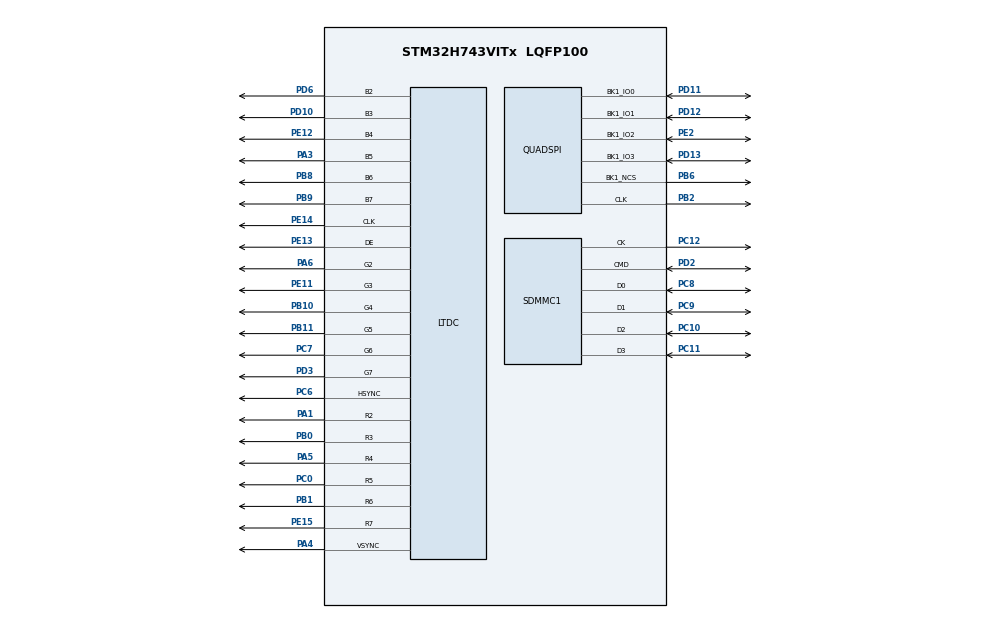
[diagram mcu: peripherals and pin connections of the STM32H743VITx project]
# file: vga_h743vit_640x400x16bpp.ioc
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CORTEX_M7.CPU_DCache=Disabled
CORTEX_M7.CPU_ICache=Enabled
DMA2D.ColorMode=DMA2D_OUTPUT_RGB565
FATFS._FS_LOCK=5
FATFS._FS_NORTC=0
FATFS._MAX_SS=4096
FATFS._USE_LFN=1
LTDC.ActiveH=400
LTDC.ActiveW=640
LTDC.Alpha_L0=255
LTDC.BlendingFactor1_L0=LTDC_BLENDING_FACTOR1_PAxCA
LTDC.BlendingFactor2_L0=LTDC_BLENDING_FACTOR2_PAxCA
LTDC.HBP=48
LTDC.HFP=16
LTDC.HSync=96
LTDC.ImageHeight_L0=400
LTDC.ImageWidth_L0=640
LTDC.Layers=0
LTDC.PixelFormat_L0=LTDC_PIXEL_FORMAT_RGB565
LTDC.VBP=73
LTDC.VFP=50
LTDC.VSync=2
LTDC.WindowX1_L0=640
LTDC.WindowY1_L0=400
Mcu.Family=STM32H7
Mcu.Name=STM32H743VITx
Mcu.Package=LQFP100
NVIC.PriorityGroup=NVIC_PRIORITYGROUP_4
NVIC.SDMMC1_IRQn=true\:0\:0\:false\:false\:true\:true
NVIC.TIM7_IRQn=true\:0\:0\:false\:false\:true\:false
NVIC.TimeBase=TIM7_IRQn
NVIC.TimeBaseIP=TIM7
PA1.Mode=RGB666
PA1.Signal=LTDC_R2
PA13.Mode=Trace_Asynchronous_SW
PA13.Signal=SYS_JTMS-SWDIO
PA14.Mode=Trace_Asynchronous_SW
PA14.Signal=SYS_JTCK-SWCLK
PA3.Mode=RGB666
PA3.Signal=LTDC_B5
PA4.Mode=RGB666
PA4.Signal=LTDC_VSYNC
PA5.Mode=RGB666
PA5.Signal=LTDC_R4
PA6.Mode=RGB666
PA6.Signal=LTDC_G2
PB0.Mode=RGB666
PB0.Signal=LTDC_R3
PB1.Mode=RGB666
PB1.Signal=LTDC_R6
PB10.Mode=RGB666
PB10.Signal=LTDC_G4
PB11.Mode=RGB666
PB11.Signal=LTDC_G5
PB2.Mode=Single Bank 1
PB2.Signal=QUADSPI_CLK
PB3.Mode=Trace_Asynchronous_SW
PB3.Signal=SYS_JTDO-SWO
PB6.Mode=Single Bank 1
PB6.Signal=QUADSPI_BK1_NCS
PB8.Mode=RGB666
PB8.Signal=LTDC_B6
PB9.Mode=RGB666
PB9.Signal=LTDC_B7
PC0.Mode=RGB666
PC0.Signal=LTDC_R5
PC10.Mode=SD_4_bits_Wide_bus
PC10.Signal=SDMMC1_D2
PC11.Mode=SD_4_bits_Wide_bus
PC11.Signal=SDMMC1_D3
PC12.Mode=SD_4_bits_Wide_bus
PC12.Signal=SDMMC1_CK
PC14-OSC32_IN.Mode=LSE-External-Oscillator
PC14-OSC32_IN.Signal=RCC_OSC32_IN
PC15-OSC32_OUT.Mode=LSE-External-Oscillator
PC15-OSC32_OUT.Signal=RCC_OSC32_OUT
PC6.Mode=RGB666
PC6.Signal=LTDC_HSYNC
PC7.Mode=RGB666
PC7.Signal=LTDC_G6
PC8.Mode=SD_4_bits_Wide_bus
PC8.Signal=SDMMC1_D0
PC9.Mode=SD_4_bits_Wide_bus
PC9.Signal=SDMMC1_D1
PD10.Mode=RGB666
PD10.Signal=LTDC_B3
PD11.Mode=Single Bank 1
PD11.Signal=QUADSPI_BK1_IO0
PD12.Mode=Single Bank 1
PD12.Signal=QUADSPI_BK1_IO1
PD13.Mode=Single Bank 1
PD13.Signal=QUADSPI_BK1_IO3
PD2.Mode=SD_4_bits_Wide_bus
PD2.Signal=SDMMC1_CMD
PD3.Mode=RGB666
PD3.Signal=LTDC_G7
PD6.Mode=RGB666
PD6.Signal=LTDC_B2
PE11.Mode=RGB666
PE11.Signal=LTDC_G3
PE12.Mode=RGB666
PE12.Signal=LTDC_B4
PE13.Mode=RGB666
PE13.Signal=LTDC_DE
PE14.Mode=RGB666
PE14.Signal=LTDC_CLK
PE15.Mode=RGB666
PE15.Signal=LTDC_R7
PE2.Mode=Single Bank 1
PE2.Signal=QUADSPI_BK1_IO2
PH0-OSC_IN.Mode=HSE-External-Oscillator
PH0-OSC_IN.Signal=RCC_OSC_IN
PH1-OSC_OUT.Mode=HSE-External-Oscillator
PH1-OSC_OUT.Signal=RCC_OSC_OUT
ProjectManager.HeapSize=0x200
ProjectManager.StackSize=0x800
ProjectManager.TargetToolchain=TrueSTUDIO
RCC.ADCFreq_Value=50390625
RCC.APB1Freq_Value=100000000
RCC.APB2Freq_Value=100000000
RCC.APB3Freq_Value=100000000
RCC.APB4Freq_Value=100000000
RCC.CortexFreq_Value=400000000
RCC.D1PPRE=RCC_APB3_DIV2
RCC.D2PPRE1=RCC_APB1_DIV2
RCC.D2PPRE2=RCC_APB2_DIV2
RCC.D3PPRE=RCC_APB4_DIV2
RCC.DIVM1=5
RCC.DIVM3=25
RCC.DIVN1=160
RCC.DIVN3=201
RCC.DIVQ3=4
RCC.DIVR3=8
RCC.HCLKFreq_Value=200000000
RCC.HPRE=RCC_HCLK_DIV2
RCC.PLLSourceVirtual=RCC_PLLSOURCE_HSE
RCC.RTCClockSelection=RCC_RTCCLKSOURCE_LSE
RCC.SYSCLKFreq_VALUE=400000000
RCC.SYSCLKSource=RCC_SYSCLKSOURCE_PLLCLK
RCC.USBCLockSelection=RCC_USBCLKSOURCE_PLL3
RCC.USBFreq_Value=50250000
SDMMC1.ClockDiv=2
VP_DMA2D_VS_DMA2D.Mode=DMA2D_Activate
VP_FATFS_VS_SDIO.Mode=SDIO
VP_JPEG_VS_JPEG.Mode=JPEG_Activate
VP_LIBJPEG_VS_JPEGLIB.Mode=Enabled
VP_RTC_VS_RTC_Activate.Mode=RTC_Enabled
VP_SYS_VS_tim7.Mode=TIM7
board=custom

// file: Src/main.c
/**
  ******************************************************************************
  * @file           : main.c
  * @brief          : Main program body
  ******************************************************************************
  * This notice applies to any and all portions of this file
  * that are not between comment pairs USER CODE BEGIN and
  * USER CODE END. Other portions of this file, whether
  * inserted by the user or by software development tools
  * are owned by their respective copyright owners.
  *
  * Copyright (c) 2020 STMicroelectronics International N.V.
  * All rights reserved.
  *
  * Redistribution and use in source and binary forms, with or without
  * modification, are permitted, provided that the following conditions are met:
  *
  * 1. Redistribution of source code must retain the above copyright notice,
  *    this list of conditions and the following disclaimer.
  * 2. Redistributions in binary form must reproduce the above copyright notice,
  *    this list of conditions and the following disclaimer in the documentation
  *    and/or other materials provided with the distribution.
  * 3. Neither the name of STMicroelectronics nor the names of other
  *    contributors to this software may be used to endorse or promote products
  *    derived from this software without specific written permission.
  * 4. This software, including modifications and/or derivative works of this
  *    software, must execute solely and exclusively on microcontroller or
  *    microprocessor devices manufactured by or for STMicroelectronics.
  * 5. Redistribution and use of this software other than as permitted under
  *    this license is void and will automatically terminate your rights under
  *    this license.
  *
  * THIS SOFTWARE IS PROVIDED BY STMICROELECTRONICS AND CONTRIBUTORS "AS IS"
  * AND ANY EXPRESS, IMPLIED OR STATUTORY WARRANTIES, INCLUDING, BUT NOT
  * LIMITED TO, THE IMPLIED WARRANTIES OF MERCHANTABILITY, FITNESS FOR A
  * PARTICULAR PURPOSE AND NON-INFRINGEMENT OF THIRD PARTY INTELLECTUAL PROPERTY
  * RIGHTS ARE DISCLAIMED TO THE FULLEST EXTENT PERMITTED BY LAW. IN NO EVENT
  * SHALL STMICROELECTRONICS OR CONTRIBUTORS BE LIABLE FOR ANY DIRECT, INDIRECT,
  * INCIDENTAL, SPECIAL, EXEMPLARY, OR CONSEQUENTIAL DAMAGES (INCLUDING, BUT NOT
  * LIMITED TO, PROCUREMENT OF SUBSTITUTE GOODS OR SERVICES; LOSS OF USE, DATA,
  * OR PROFITS; OR BUSINESS INTERRUPTION) HOWEVER CAUSED AND ON ANY THEORY OF
  * LIABILITY, WHETHER IN CONTRACT, STRICT LIABILITY, OR TORT (INCLUDING
  * NEGLIGENCE OR OTHERWISE) ARISING IN ANY WAY OUT OF THE USE OF THIS SOFTWARE,
  * EVEN IF ADVISED OF THE POSSIBILITY OF SUCH DAMAGE.
  *
  ******************************************************************************
  */
#include "main.h"
#include "stm32h7xx_hal.h"
#include "fatfs.h"
#include "libjpeg.h"

DMA2D_HandleTypeDef hdma2d;

JPEG_HandleTypeDef hjpeg;

LTDC_HandleTypeDef hltdc;

QSPI_HandleTypeDef hqspi;

RTC_HandleTypeDef hrtc;

SD_HandleTypeDef hsd1;

/* USER CODE BEGIN PV */
/* Private variables ---------------------------------------------------------*/
void mainApp(void);
/* USER CODE END PV */

void SystemClock_Config(void);
static void MX_GPIO_Init(void);
static void MX_LTDC_Init(void);
static void MX_QUADSPI_Init(void);
static void MX_SDMMC1_SD_Init(void);
static void MX_DMA2D_Init(void);
static void MX_RTC_Init(void);
static void MX_JPEG_Init(void);

/* USER CODE BEGIN PFP */
/* Private function prototypes -----------------------------------------------*/

/* USER CODE END PFP */

int main(void)
{

  /* Enable I-Cache-------------------------------------------------------------*/
  SCB_EnableICache();

  /* MCU Configuration----------------------------------------------------------*/

  /* Reset of all peripherals, Initializes the Flash interface and the Systick. */
  HAL_Init();

  /* Configure the system clock */
  SystemClock_Config();

  /* Initialize all configured peripherals */
  MX_GPIO_Init();
  MX_LTDC_Init();
  MX_QUADSPI_Init();
  MX_SDMMC1_SD_Init();
  MX_DMA2D_Init();
  MX_FATFS_Init();
  MX_RTC_Init();
  MX_LIBJPEG_Init();
  MX_JPEG_Init();

  /* Infinite loop */
  /* USER CODE BEGIN WHILE */
  mainApp();
  while (1)
  {

  /* USER CODE END WHILE */

  }

}

void SystemClock_Config(void)
{

  RCC_OscInitTypeDef RCC_OscInitStruct;
  RCC_ClkInitTypeDef RCC_ClkInitStruct;
  RCC_PeriphCLKInitTypeDef PeriphClkInitStruct;

    /**Supply configuration update enable
    */
  MODIFY_REG(PWR->CR3, PWR_CR3_SCUEN, 0);

    /**Configure the main internal regulator output voltage
    */
  __HAL_PWR_VOLTAGESCALING_CONFIG(PWR_REGULATOR_VOLTAGE_SCALE1);

  while ((PWR->D3CR & (PWR_D3CR_VOSRDY)) != PWR_D3CR_VOSRDY)
  {

  }
    /**Configure LSE Drive Capability
    */
  HAL_PWR_EnableBkUpAccess();

  __HAL_RCC_LSEDRIVE_CONFIG(RCC_LSEDRIVE_LOW);

    /**Macro to configure the PLL clock source
    */
  __HAL_RCC_PLL_PLLSOURCE_CONFIG(RCC_PLLSOURCE_HSE);

    /**Initializes the CPU, AHB and APB busses clocks
    */
  RCC_OscInitStruct.OscillatorType = RCC_OSCILLATORTYPE_HSE|RCC_OSCILLATORTYPE_LSE;
  RCC_OscInitStruct.HSEState = RCC_HSE_ON;
  RCC_OscInitStruct.LSEState = RCC_LSE_ON;
  RCC_OscInitStruct.PLL.PLLState = RCC_PLL_ON;
  RCC_OscInitStruct.PLL.PLLSource = RCC_PLLSOURCE_HSE;
  RCC_OscInitStruct.PLL.PLLM = 5;
  RCC_OscInitStruct.PLL.PLLN = 160;
  RCC_OscInitStruct.PLL.PLLP = 2;
  RCC_OscInitStruct.PLL.PLLQ = 2;
  RCC_OscInitStruct.PLL.PLLR = 2;
  RCC_OscInitStruct.PLL.PLLRGE = RCC_PLL1VCIRANGE_2;
  RCC_OscInitStruct.PLL.PLLVCOSEL = RCC_PLL1VCOWIDE;
  RCC_OscInitStruct.PLL.PLLFRACN = 0;
  if (HAL_RCC_OscConfig(&RCC_OscInitStruct) != HAL_OK)
  {
    _Error_Handler(__FILE__, __LINE__);
  }

    /**Initializes the CPU, AHB and APB busses clocks
    */
  RCC_ClkInitStruct.ClockType = RCC_CLOCKTYPE_HCLK|RCC_CLOCKTYPE_SYSCLK
                              |RCC_CLOCKTYPE_PCLK1|RCC_CLOCKTYPE_PCLK2
                              |RCC_CLOCKTYPE_D3PCLK1|RCC_CLOCKTYPE_D1PCLK1;
  RCC_ClkInitStruct.SYSCLKSource = RCC_SYSCLKSOURCE_PLLCLK;
  RCC_ClkInitStruct.SYSCLKDivider = RCC_SYSCLK_DIV1;
  RCC_ClkInitStruct.AHBCLKDivider = RCC_HCLK_DIV2;
  RCC_ClkInitStruct.APB3CLKDivider = RCC_APB3_DIV2;
  RCC_ClkInitStruct.APB1CLKDivider = RCC_APB1_DIV2;
  RCC_ClkInitStruct.APB2CLKDivider = RCC_APB2_DIV2;
  RCC_ClkInitStruct.APB4CLKDivider = RCC_APB4_DIV2;

  if (HAL_RCC_ClockConfig(&RCC_ClkInitStruct, FLASH_LATENCY_2) != HAL_OK)
  {
    _Error_Handler(__FILE__, __LINE__);
  }

  PeriphClkInitStruct.PeriphClockSelection = RCC_PERIPHCLK_RTC|RCC_PERIPHCLK_LTDC
                              |RCC_PERIPHCLK_SDMMC|RCC_PERIPHCLK_QSPI;
  PeriphClkInitStruct.PLL3.PLL3M = 25;
  PeriphClkInitStruct.PLL3.PLL3N = 201;
  PeriphClkInitStruct.PLL3.PLL3P = 2;
  PeriphClkInitStruct.PLL3.PLL3Q = 4;
  PeriphClkInitStruct.PLL3.PLL3R = 8;
  PeriphClkInitStruct.PLL3.PLL3RGE = RCC_PLL3VCIRANGE_0;
  PeriphClkInitStruct.PLL3.PLL3VCOSEL = RCC_PLL3VCOWIDE;
  PeriphClkInitStruct.PLL3.PLL3FRACN = 0;
  PeriphClkInitStruct.QspiClockSelection = RCC_QSPICLKSOURCE_D1HCLK;
  PeriphClkInitStruct.SdmmcClockSelection = RCC_SDMMCCLKSOURCE_PLL;
  PeriphClkInitStruct.RTCClockSelection = RCC_RTCCLKSOURCE_LSE;
  if (HAL_RCCEx_PeriphCLKConfig(&PeriphClkInitStruct) != HAL_OK)
  {
    _Error_Handler(__FILE__, __LINE__);
  }

    /**Configure the Systick interrupt time
    */
  HAL_SYSTICK_Config(SystemCoreClock/1000);

    /**Configure the Systick
    */
  HAL_SYSTICK_CLKSourceConfig(SYSTICK_CLKSOURCE_HCLK);

  /* SysTick_IRQn interrupt configuration */
  HAL_NVIC_SetPriority(SysTick_IRQn, 0, 0);
}

/* DMA2D init function */
static void MX_DMA2D_Init(void)
{

  hdma2d.Instance = DMA2D;
  hdma2d.Init.Mode = DMA2D_M2M;
  hdma2d.Init.ColorMode = DMA2D_OUTPUT_RGB565;
  hdma2d.Init.OutputOffset = 0;
  hdma2d.LayerCfg[1].InputOffset = 0;
  hdma2d.LayerCfg[1].InputColorMode = DMA2D_INPUT_RGB565;
  hdma2d.LayerCfg[1].AlphaMode = DMA2D_NO_MODIF_ALPHA;
  hdma2d.LayerCfg[1].InputAlpha = 0;
  hdma2d.LayerCfg[1].ChromaSubSampling = DMA2D_NO_CSS;
  if (HAL_DMA2D_Init(&hdma2d) != HAL_OK)
  {
    _Error_Handler(__FILE__, __LINE__);
  }

  if (HAL_DMA2D_ConfigLayer(&hdma2d, 1) != HAL_OK)
  {
    _Error_Handler(__FILE__, __LINE__);
  }

}

/* JPEG init function */
static void MX_JPEG_Init(void)
{

  hjpeg.Instance = JPEG;
  if (HAL_JPEG_Init(&hjpeg) != HAL_OK)
  {
    _Error_Handler(__FILE__, __LINE__);
  }

}

/* LTDC init function */
static void MX_LTDC_Init(void)
{

  LTDC_LayerCfgTypeDef pLayerCfg;

  hltdc.Instance = LTDC;
  hltdc.Init.HSPolarity = LTDC_HSPOLARITY_AL;
  hltdc.Init.VSPolarity = LTDC_VSPOLARITY_AL;
  hltdc.Init.DEPolarity = LTDC_DEPOLARITY_AL;
  hltdc.Init.PCPolarity = LTDC_PCPOLARITY_IPC;
  hltdc.Init.HorizontalSync = 95;
  hltdc.Init.VerticalSync = 1;
  hltdc.Init.AccumulatedHBP = 143;
  hltdc.Init.AccumulatedVBP = 74;
  hltdc.Init.AccumulatedActiveW = 783;
  hltdc.Init.AccumulatedActiveH = 474;
  hltdc.Init.TotalWidth = 799;
  hltdc.Init.TotalHeigh = 524;
  hltdc.Init.Backcolor.Blue = 0;
  hltdc.Init.Backcolor.Green = 0;
  hltdc.Init.Backcolor.Red = 0;
  if (HAL_LTDC_Init(&hltdc) != HAL_OK)
  {
    _Error_Handler(__FILE__, __LINE__);
  }

  pLayerCfg.WindowX0 = 0;
  pLayerCfg.WindowX1 = 640;
  pLayerCfg.WindowY0 = 0;
  pLayerCfg.WindowY1 = 400;
  pLayerCfg.PixelFormat = LTDC_PIXEL_FORMAT_RGB565;
  pLayerCfg.Alpha = 255;
  pLayerCfg.Alpha0 = 0;
  pLayerCfg.BlendingFactor1 = LTDC_BLENDING_FACTOR1_PAxCA;
  pLayerCfg.BlendingFactor2 = LTDC_BLENDING_FACTOR2_PAxCA;
  pLayerCfg.FBStartAdress = 0;
  pLayerCfg.ImageWidth = 640;
  pLayerCfg.ImageHeight = 400;
  pLayerCfg.Backcolor.Blue = 0;
  pLayerCfg.Backcolor.Green = 0;
  pLayerCfg.Backcolor.Red = 0;
  if (HAL_LTDC_ConfigLayer(&hltdc, &pLayerCfg, 0) != HAL_OK)
  {
    _Error_Handler(__FILE__, __LINE__);
  }

}

/* QUADSPI init function */
static void MX_QUADSPI_Init(void)
{

  /* QUADSPI parameter configuration*/
  hqspi.Instance = QUADSPI;
  hqspi.Init.ClockPrescaler = 255;
  hqspi.Init.FifoThreshold = 1;
  hqspi.Init.SampleShifting = QSPI_SAMPLE_SHIFTING_NONE;
  hqspi.Init.FlashSize = 1;
  hqspi.Init.ChipSelectHighTime = QSPI_CS_HIGH_TIME_1_CYCLE;
  hqspi.Init.ClockMode = QSPI_CLOCK_MODE_0;
  hqspi.Init.FlashID = QSPI_FLASH_ID_1;
  hqspi.Init.DualFlash = QSPI_DUALFLASH_DISABLE;
  if (HAL_QSPI_Init(&hqspi) != HAL_OK)
  {
    _Error_Handler(__FILE__, __LINE__);
  }

}

/* RTC init function */
static void MX_RTC_Init(void)
{

    /**Initialize RTC Only
    */
  hrtc.Instance = RTC;
  hrtc.Init.HourFormat = RTC_HOURFORMAT_24;
  hrtc.Init.AsynchPrediv = 127;
  hrtc.Init.SynchPrediv = 255;
  hrtc.Init.OutPut = RTC_OUTPUT_DISABLE;
  hrtc.Init.OutPutPolarity = RTC_OUTPUT_POLARITY_HIGH;
  hrtc.Init.OutPutType = RTC_OUTPUT_TYPE_OPENDRAIN;
  hrtc.Init.OutPutRemap = RTC_OUTPUT_REMAP_NONE;
  if (HAL_RTC_Init(&hrtc) != HAL_OK)
  {
    _Error_Handler(__FILE__, __LINE__);
  }

}

/* SDMMC1 init function */
static void MX_SDMMC1_SD_Init(void)
{

  hsd1.Instance = SDMMC1;
  hsd1.Init.ClockEdge = SDMMC_CLOCK_EDGE_RISING;
  hsd1.Init.ClockPowerSave = SDMMC_CLOCK_POWER_SAVE_DISABLE;
  hsd1.Init.BusWide = SDMMC_BUS_WIDE_4B;
  hsd1.Init.HardwareFlowControl = SDMMC_HARDWARE_FLOW_CONTROL_DISABLE;
  hsd1.Init.ClockDiv = 0;

}

/** Configure pins as
        * Analog
        * Input
        * Output
        * EVENT_OUT
        * EXTI
*/
static void MX_GPIO_Init(void)
{

  /* GPIO Ports Clock Enable */
  __HAL_RCC_GPIOE_CLK_ENABLE();
  __HAL_RCC_GPIOC_CLK_ENABLE();
  __HAL_RCC_GPIOH_CLK_ENABLE();
  __HAL_RCC_GPIOA_CLK_ENABLE();
  __HAL_RCC_GPIOB_CLK_ENABLE();
  __HAL_RCC_GPIOD_CLK_ENABLE();

}

void HAL_TIM_PeriodElapsedCallback(TIM_HandleTypeDef *htim)
{
  if (htim->Instance == TIM7) {
    HAL_IncTick();
  }
}

void _Error_Handler(char *file, int line)
{
  while(1)
  {
  }
}

/************************ (C) COPYRIGHT STMicroelectronics *****END OF FILE****/
